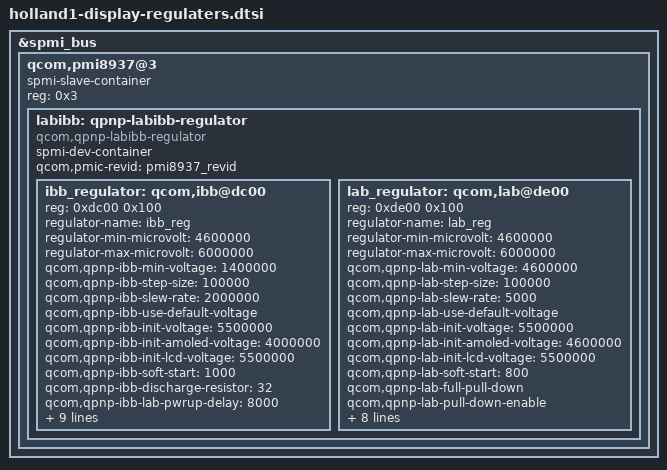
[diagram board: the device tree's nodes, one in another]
/*
 * Copyright (c) 2015-2016, The Linux Foundation. All rights reserved.
 *
 * Copyright (c) 2020, Shubham-Panwar.
 *
 * This program is free software; you can redistribute it and/or modify
 * it under the terms of the GNU General Public License version 2 and
 * only version 2 as published by the Free Software Foundation.
 *
 * This program is distributed in the hope that it will be useful,
 * but WITHOUT ANY WARRANTY; without even the implied warranty of
 * MERCHANTABILITY or FITNESS FOR A PARTICULAR PURPOSE.  See the
 * GNU General Public License for more details.
 */
 
&spmi_bus {

    qcom,pmi8937@3 {
		spmi-slave-container;
		reg = <0x3>;
		#address-cells = <1>;
		#size-cells = <1>;
        
        labibb: qpnp-labibb-regulator {
			spmi-dev-container;
			compatible = "qcom,qpnp-labibb-regulator";
			#address-cells = <1>;
			#size-cells = <1>;
			qcom,pmic-revid = <&pmi8937_revid>;

			ibb_regulator: qcom,ibb@dc00 {
				reg = <0xdc00 0x100>;
				reg-names = "ibb_reg";
				regulator-name = "ibb_reg";
				regulator-min-microvolt = <4600000>;
				regulator-max-microvolt = <6000000>;
				qcom,qpnp-ibb-min-voltage = <1400000>;
				qcom,qpnp-ibb-step-size = <100000>;
				qcom,qpnp-ibb-slew-rate = <2000000>;
				qcom,qpnp-ibb-use-default-voltage;
				qcom,qpnp-ibb-init-voltage = <5500000>;
				qcom,qpnp-ibb-init-amoled-voltage = <4000000>;
				qcom,qpnp-ibb-init-lcd-voltage = <5500000>;
                qcom,qpnp-ibb-soft-start = <1000>;
    			qcom,qpnp-ibb-discharge-resistor = <32>;
				qcom,qpnp-ibb-lab-pwrup-delay = <8000>;
				qcom,qpnp-ibb-lab-pwrdn-delay = <8000>;
				qcom,qpnp-ibb-en-discharge;
				qcom,qpnp-ibb-full-pull-down;
				qcom,qpnp-ibb-pull-down-enable;
				qcom,qpnp-ibb-switching-clock-frequency = <1480>;
				qcom,qpnp-ibb-limit-maximum-current = <1550>;
				qcom,qpnp-ibb-debounce-cycle = <16>;
				qcom,qpnp-ibb-limit-max-current-enable;
				qcom,qpnp-ibb-ps-enable;
			};

			lab_regulator: qcom,lab@de00 {
				reg = <0xde00 0x100>;
				reg-names = "lab";
				regulator-name = "lab_reg";
				regulator-min-microvolt = <4600000>;
				regulator-max-microvolt = <6000000>;
				qcom,qpnp-lab-min-voltage = <4600000>;
				qcom,qpnp-lab-step-size = <100000>;
				qcom,qpnp-lab-slew-rate = <5000>;
				qcom,qpnp-lab-use-default-voltage;
				qcom,qpnp-lab-init-voltage = <5500000>;
				qcom,qpnp-lab-init-amoled-voltage = <4600000>;
				qcom,qpnp-lab-init-lcd-voltage = <5500000>;
				qcom,qpnp-lab-soft-start = <800>;
				qcom,qpnp-lab-full-pull-down;
				qcom,qpnp-lab-pull-down-enable;
				qcom,qpnp-lab-switching-clock-frequency = <1600>;
				qcom,qpnp-lab-limit-maximum-current = <800>;
				qcom,qpnp-lab-limit-max-current-enable;
				qcom,qpnp-lab-ps-threshold = <40>;
				qcom,qpnp-lab-ps-enable;
				qcom,qpnp-lab-nfet-size = <100>;
				qcom,qpnp-lab-pfet-size = <100>;
				qcom,qpnp-lab-max-precharge-time = <500>;
			};
		};
    };
};
